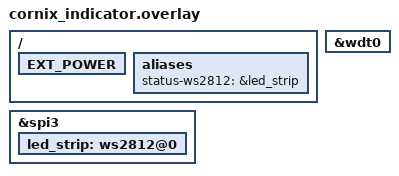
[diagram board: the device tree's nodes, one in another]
&spi3 {
    status = "okay";

    led_strip: ws2812@0 {
        status = "okay";
    };
};

/ {
    EXT_POWER {
        status = "okay";
    };

    aliases {
        status-ws2812 = &led_strip;
    };
};

/* DIAG (diag/14-reconnect-heartbeat): enable the watchdog so src/diag_root.c can
 * arm it for #14 auto-recovery from a silent interrupt-locked hard hang. */
&wdt0 {
    status = "okay";
};

//vim: set ft=dts:
